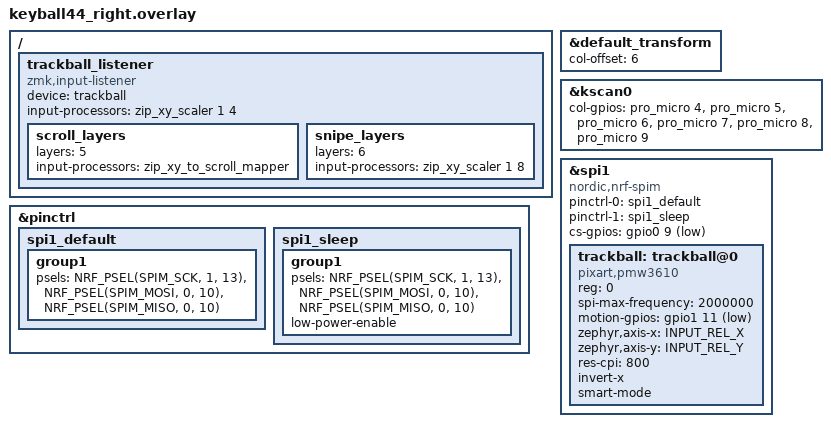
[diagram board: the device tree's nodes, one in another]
/*
 * Copyright (c) 2020 ZMK Contributors
 *
 * SPDX-License-Identifier: MIT
 */

#include "keyball44.dtsi"
#include <dt-bindings/input/input-event-codes.h>
#include <input/processors.dtsi>

&default_transform {
    col-offset = <6>;
};

&kscan0 {
	col-gpios
		= <&pro_micro 4 GPIO_ACTIVE_HIGH>
		, <&pro_micro 5 GPIO_ACTIVE_HIGH>
		, <&pro_micro 6 GPIO_ACTIVE_HIGH>
		, <&pro_micro 7 GPIO_ACTIVE_HIGH>
		, <&pro_micro 8 GPIO_ACTIVE_HIGH>
        , <&pro_micro 9 GPIO_ACTIVE_HIGH>
		;
};

&pinctrl {
    spi1_default: spi1_default {
        group1 {
            psels = <NRF_PSEL(SPIM_SCK, 1, 13)>,
                <NRF_PSEL(SPIM_MOSI, 0, 10)>,
                <NRF_PSEL(SPIM_MISO, 0, 10)>;
        };
    };

    spi1_sleep: spi1_sleep {
        group1 {
            psels = <NRF_PSEL(SPIM_SCK, 1, 13)>,
                <NRF_PSEL(SPIM_MOSI, 0, 10)>,
                <NRF_PSEL(SPIM_MISO, 0, 10)>;
            low-power-enable;
        };
    };
};

&spi1 {
    status = "okay";
    compatible = "nordic,nrf-spim";
    pinctrl-0 = <&spi1_default>;
    pinctrl-1 = <&spi1_sleep>;
    pinctrl-names = "default", "sleep";
    cs-gpios = <&gpio0 9 GPIO_ACTIVE_LOW>;

    trackball: trackball@0 {
        status = "okay";
        compatible = "pixart,pmw3610";
        reg = <0>;
        spi-max-frequency = <2000000>;
        motion-gpios = <&gpio1 11 (GPIO_ACTIVE_LOW | GPIO_PULL_UP)>;
        zephyr,axis-x = <INPUT_REL_X>;
        zephyr,axis-y = <INPUT_REL_Y>;
        res-cpi = <800>;
        invert-x;
        smart-mode;
    };
};

/ {
  trackball_listener: trackball_listener {
    compatible = "zmk,input-listener";
    device = <&trackball>;
    input-processors = <&zip_xy_scaler 1 4>;

    scroll_layers: scroll_layers {
      layers = <5>;
      input-processors = <&zip_xy_to_scroll_mapper>;
    };

    snipe_layers: snipe_layers {
      layers = <6>;
      input-processors = <&zip_xy_scaler 1 8>;
    };
  };
};
